# NUC1xx_registers register map
File version: 0.1
CPU: 
Registers are 32-bit, read-write, reset 0x0 unless marked. A register's access mark holds for its fields unless they carry their own. Offsets are from the block's base; [hi:lo] are bit positions; lines under a group give offsets from that group.

## RTC — Registers group
Base 0x40008000
0x00 INIR — RTC Initiation Register
  [0] Active ro — RTC Active Status (Read only), 0: RTC is at reset state 1: RTC is at normal active state.
  [31:0] INIR wo — RTC Initiation When chip is power on, RTC timer counter is at unknown state because RTC timer counter reset is individual with chip reset; user has to write a number (0x a5eb1357) to INIR to reset RTC controller to initialize RTC controller.
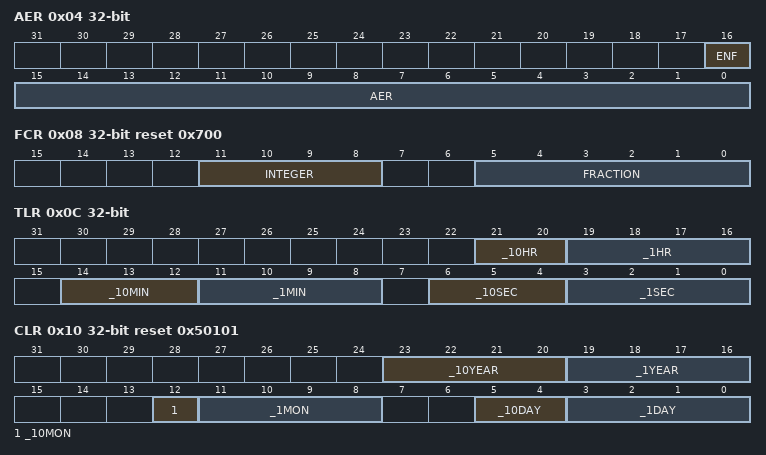
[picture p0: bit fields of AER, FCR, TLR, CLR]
0x04 AER — RTC Access Enable Register
  [16] ENF ro — RTC Register Access Enable Flag (Read only) 1 = RTC register read/write enable 0 = RTC register read/write disable This bit will be set after AER[15:0] register is load a 0xA965, and be clear automatically 512 RTC clock or AER[15:0] is not 0xA965.Register\AER.ENF 1 0 INIR R/W R/W AER R/W R/W FCR R/W - TLR R/W R CLR R/W R TSSR R/W R/W DWR R/W R TAR R/W - CAR R/W - LIR R R RIER R/W R/W RIIR R/C R/C TTR R/W -
  [15:0] AER wo — RTC Register Access Enable Password (Write only) 0xA965 = Enable RTC access Others = Disable RTC access
0x08 FCR reset 0x700 (reset mask 0xFFFFF8FF) — RTC Frequency Compensation Register
  [11:8] INTEGER — Integer Part Integer part of detected value FCR[11:8] Integer part of detected value FCR[11:8] 32776 1111 32768 0111 32775 1110 32767 0110 32774 1101 32766 0101 32773 1100 32765 0100 32772 1011 32764 0011 32771 1010 32763 0010 32770 1001 32762 0001 32769 1000 32761 0000
  [5:0] FRACTION — Fraction Part Formula = (fraction part of detected value) x 60 Note: Digit in FCR must be expressed as hexadecimal number. Refer to 5.8.4.4 for the examples.
0x0C TLR — Time Loading Register
  [21:20] _10HR — 10 Hour Time Digit (0~2)
  [19:16] _1HR — 1 Hour Time Digit (0~9)
  [14:12] _10MIN — 10 Min Time Digit (0~5)
  [11:8] _1MIN — 1 Min Time Digit (0~9)
  [6:4] _10SEC — 10 Sec Time Digit (0~5)
  [3:0] _1SEC — 1 Sec Time Digit (0~9)
0x10 CLR reset 0x50101 (reset mask 0xFFFAFEFE) — Calendar Loading Register
  [23:20] _10YEAR — 10-Year Calendar Digit (0~9)
  [19:16] _1YEAR — 1-Year Calendar Digit (0~9)
  [12] _10MON — 10-Month Calendar Digit (0~1)
  [11:8] _1MON — 1-Month Calendar Digit (0~9)
  [5:4] _10DAY — 10-Day Calendar Digit (0~3)
  [3:0] _1DAY — 1-Day Calendar Digit (0~9)
0x14 TSSR reset 0x1 (reset mask 0xFFFFFFFE) — Time Scale Selection Register
  [0] _24H_12H — 24-Hour / 12-Hour Time Scale Selection It indicate that TLR and TAR are in 24-hour time mode or 12-hour time mode 1 = select 24-hour time scale 0 = select 12-hour time scale with AM and PM indication 24-hour time scale 12-hour time scale 24-hour time scale 12-hour time scale (PM time + 20) 00 12(AM12) 12 32(PM12) 01 01(AM01) 13 21(PM01) 02 02(AM02) 14 22(PM02) 03 03(AM03) 15 23(PM03) 04 04(AM04) 16 24(PM04) 05 05(AM05) 17 25(PM05) 06 06(AM06) 18 26(PM06) 07 07(AM07) 19 27(PM07) 08 08(AM08) 20 28(PM08) 09 09(AM09) 21 29(PM09) 10 10(AM10) 22 30(PM10) 11 11(AM11) 23 31(PM11)
0x18 DWR reset 0x6 (reset mask 0xFFFFFFF9) — Day of the Week Register
  [2:0] DWR — Day of the Week Register Value Day of the Week 0 Sunday 1 Monday 2 Tuesday 3 Wednesday 4 Thursday 5 Friday 6 Saturday
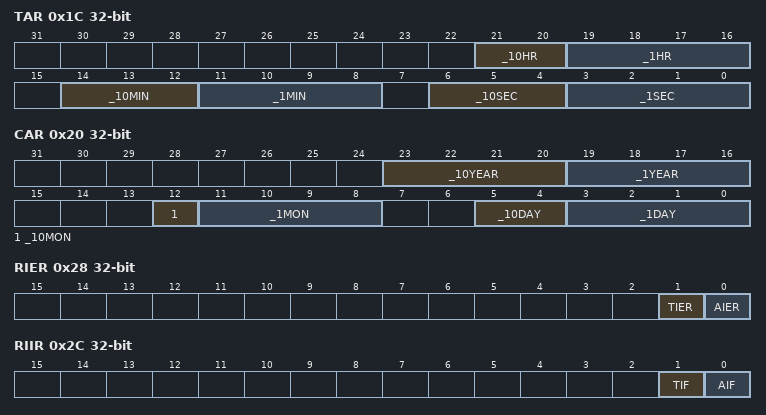
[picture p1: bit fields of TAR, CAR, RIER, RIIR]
0x1C TAR — Time Alarm Register
  [21:20] _10HR — 10 Hour Time Digit of Alarm Setting (0~2)
  [19:16] _1HR — 1 Hour Time Digit of Alarm Setting (0~9)
  [14:12] _10MIN — 10 Min Time Digit of Alarm Setting (0~5)
  [11:8] _1MIN — 1 Min Time Digit of Alarm Setting (0~9)
  [6:4] _10SEC — 10 Sec Time Digit of Alarm Setting (0~5)
  [3:0] _1SEC — 1 Sec Time Digit of Alarm Setting (0~9)
0x20 CAR — Calendar Alarm Register
  [23:20] _10YEAR — 10-Year Calendar Digit of Alarm Setting (0~9)
  [19:16] _1YEAR — 1-Year Calendar Digit of Alarm Setting (0~9)
  [12] _10MON — 10-Month Calendar Digit of Alarm Setting (0~1)
  [11:8] _1MON — 1-Month Calendar Digit of Alarm Setting (0~9)
  [5:4] _10DAY — 10-Day Calendar Digit of Alarm Setting (0~3)
  [3:0] _1DAY — 1-Day Calendar Digit of Alarm Setting (0~9)
0x24 LIR ro — RTC Leap year Indicator Register
  [0] LIR — Leap Year Indication REGISTER (Real only). 1 = It indicate that this year is leap year 0 = It indicate that this year is not a leap year
0x28 RIER — RTC Interrupt Enable Register
  [1] TIER — Time Tick Interrupt Enable 1 = RTC Time Tick Interrupt is enabled 0 = RTC Time Tick Interrupt is disabled
  [0] AIER — Alarm Interrupt Enable 1 = RTC Alarm Interrupt is enabled 0 = RTC Alarm Interrupt is disabled
0x2C RIIR — RTC Interrupt Indicator Register
  [1] TIF write-1-clears — RTC Time Tick Interrupt Flag When RTC Time Tick Interrupt is enabled (RIER.TIER=1), RTC controller will set TIF to high periodically in the period selected by TTR[2:0]. This bit is software clear by writing 1 to it. 1 = Indicates RTC Time Tick Interrupt is requested if RIER.TIER=1. 0 = Indicates RTC Time Tick Interrupt condition never occurred.
  [0] AIF write-1-clears — RTC Alarm Interrupt Flag When RTC Alarm Interrupt is enabled (RIER.AIER=1), RTC controller will set AIF to high once the RTC real time counters TLR and CLR reach the alarm setting time registers TAR and CAR. This bit is software clear by writing 1 to it. 1 = Indicates RTC Alarm Interrupt is requested if RIER.AIER=1. 0 = Indicates RTC Alarm Interrupt condition never occurred.
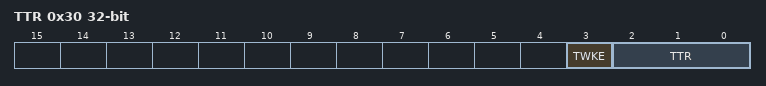
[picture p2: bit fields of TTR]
0x30 TTR — RTC Time Tick Register
  [3] TWKE — RTC Timer Wakeup CPU Function Enable Bit If TWKE is set before CPU is in power-down mode, when a RTC Time Tick occurs, CPU will be wakened up by RTC controller. 1 = Enable the Wakeup function that CPU can be waken up from power-down mode by Time Tick. 0 = Disable Wakeup CPU function by Time Tick. Note: 1. Tick timer setting follows TTR[2:0] description. 2. The CPU can also be wakeup by alarm match occur.
  [2:0] TTR — Time Tick Register The RTC time tick period for Periodic Time Tick Interrupt request. TTR[2:0] Time tick (second) 0 1 1 1/2 2 1/4 3 1/8 4 1/16 5 1/32 6 1/64 7 1/128 Note: This register can be read back after the RTC register access enable bit ENF(AER[16]) is active.
